# STM32F412xG register map
File version: 1.0
Registers are 32-bit, read-write, reset 0x0 unless marked. A register's access mark holds for its fields unless they carry their own. Offsets are from the block's base; [hi:lo] are bit positions; {n}, {i} and the like mark numbered series; 'fields as' and 'values as' point back to an identical list.

## FSMC — Flexible static memory controller
Base 0x60000000
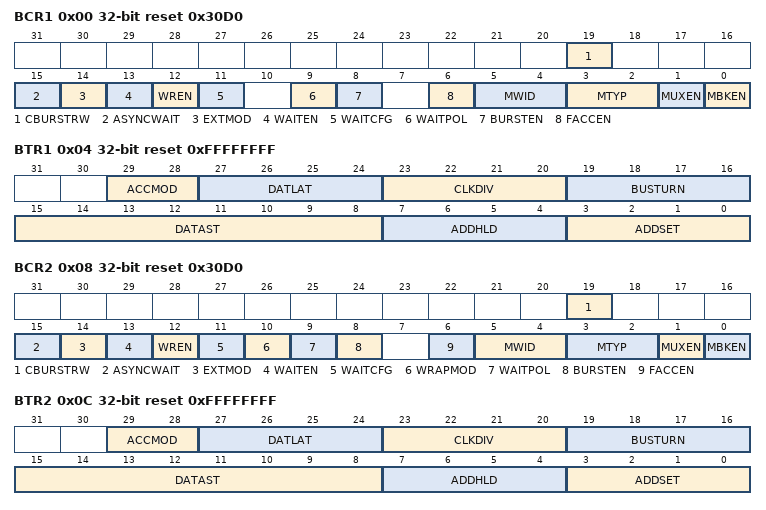
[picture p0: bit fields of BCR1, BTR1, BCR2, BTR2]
0x00 BCR1 reset 0x30D0 — SRAM/NOR-Flash chip-select control register 1
  [19] CBURSTRW, [15] ASYNCWAIT, [14] EXTMOD, [13] WAITEN, [12] WREN, [11] WAITCFG, [9] WAITPOL, [8] BURSTEN, [6] FACCEN, [5:4] MWID, [3:2] MTYP, [1] MUXEN, [0] MBKEN
0x04 BTR1 reset 0xFFFFFFFF — SRAM/NOR-Flash chip-select timing register 1
  [29:28] ACCMOD, [27:24] DATLAT, [23:20] CLKDIV, [19:16] BUSTURN, [15:8] DATAST, [7:4] ADDHLD, [3:0] ADDSET
0x08 BCR2 reset 0x30D0 — SRAM/NOR-Flash chip-select control register 2
  [19] CBURSTRW, [15] ASYNCWAIT, [14] EXTMOD, [13] WAITEN, [12] WREN, [11] WAITCFG, [10] WRAPMOD, [9] WAITPOL, [8] BURSTEN, [6] FACCEN, [5:4] MWID, [3:2] MTYP, [1] MUXEN, [0] MBKEN
0x0C BTR2 reset 0xFFFFFFFF — SRAM/NOR-Flash chip-select timing register 2
  fields as BTR1
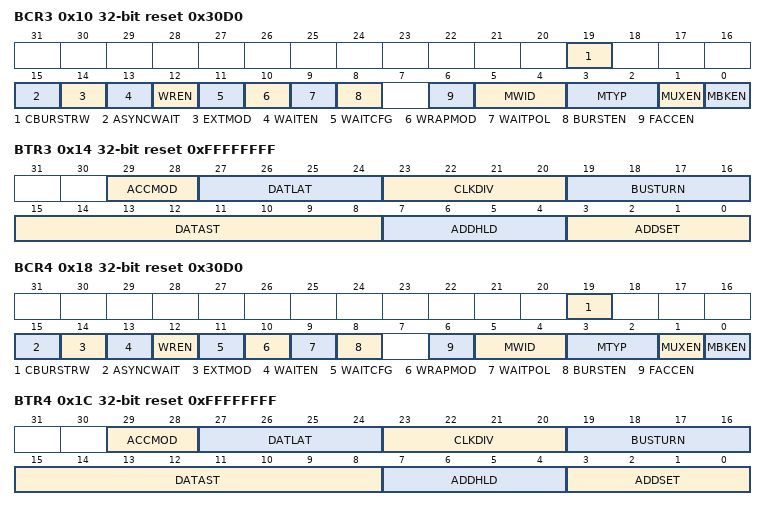
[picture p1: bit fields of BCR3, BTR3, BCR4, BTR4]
0x10 BCR3 reset 0x30D0 — SRAM/NOR-Flash chip-select control register 3
  fields as BCR2
0x14 BTR3 reset 0xFFFFFFFF — SRAM/NOR-Flash chip-select timing register 3
  fields as BTR1
0x18 BCR4 reset 0x30D0 — SRAM/NOR-Flash chip-select control register 4
  fields as BCR2
0x1C BTR4 reset 0xFFFFFFFF — SRAM/NOR-Flash chip-select timing register 4
  fields as BTR1
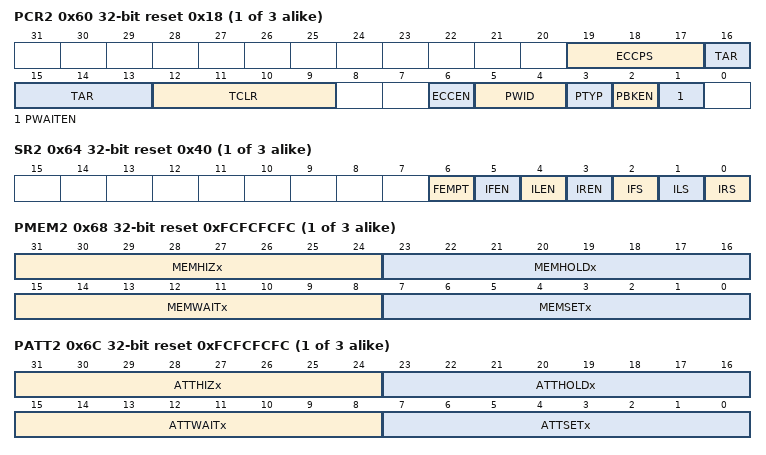
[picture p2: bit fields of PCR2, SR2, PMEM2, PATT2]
{0x20+0x20*i} PCR{i} reset 0x18 (i=2..4) — PC Card/NAND Flash control register {i}
  [19:17] ECCPS, [16:13] TAR, [12:9] TCLR, [6] ECCEN, [5:4] PWID, [3] PTYP, [2] PBKEN, [1] PWAITEN
{0x24+0x20*i} SR{i} access per field reset 0x40 (i=2..4) — FIFO status and interrupt register {i}
  [6] FEMPT ro, [5] IFEN rw, [4] ILEN rw, [3] IREN rw, [2] IFS rw, [1] ILS rw, [0] IRS rw
{0x28+0x20*i} PMEM{i} reset 0xFCFCFCFC (i=2..4) — Common memory space timing register {i}
  [31:24] MEMHIZx, [23:16] MEMHOLDx, [15:8] MEMWAITx, [7:0] MEMSETx
{0x2C+0x20*i} PATT{i} reset 0xFCFCFCFC (i=2..4) — Attribute memory space timing register {i}
  [31:24] ATTHIZx, [23:16] ATTHOLDx, [15:8] ATTWAITx, [7:0] ATTSETx
0x74 ECCR2 ro — ECC result register 2
  [31:0] ECCx
0x94 ECCR3 ro — ECC result register 3
  [31:0] ECCx
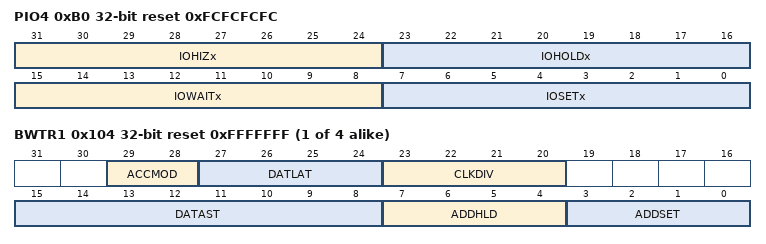
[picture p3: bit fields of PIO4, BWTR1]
0xB0 PIO4 reset 0xFCFCFCFC — I/O space timing register 4
  [31:24] IOHIZx, [23:16] IOHOLDx, [15:8] IOWAITx, [7:0] IOSETx
{0xFC+8i} BWTR{i} reset 0xFFFFFFF (i=1..4) — SRAM/NOR-Flash write timing registers {i}
  [29:28] ACCMOD, [27:24] DATLAT, [23:20] CLKDIV, [15:8] DATAST, [7:4] ADDHLD, [3:0] ADDSET

## OTG_FS_HOST — USB on the go full speed
Base 0x50000400
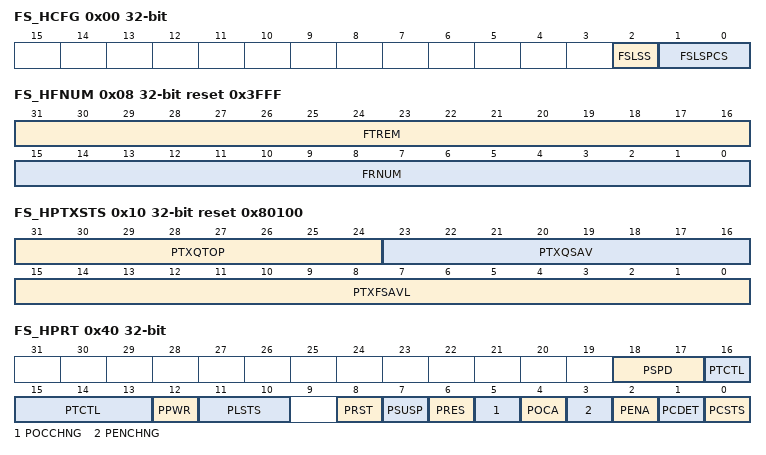
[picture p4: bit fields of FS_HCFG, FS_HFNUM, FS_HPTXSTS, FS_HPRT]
0x00 FS_HCFG access per field — OTG_FS host configuration register (OTG_FS_HCFG)
  [2] FSLSS ro — FS- and LS-only support
  [1:0] FSLSPCS rw — FS/LS PHY clock select
0x04 HFIR reset 0xEA60 — OTG_FS Host frame interval register
  [15:0] FRIVL — Frame interval
0x08 FS_HFNUM ro reset 0x3FFF — OTG_FS host frame number/frame time remaining register (OTG_FS_HFNUM)
  [31:16] FTREM — Frame time remaining
  [15:0] FRNUM — Frame number
0x10 FS_HPTXSTS access per field reset 0x80100 — OTG_FS_Host periodic transmit FIFO/queue status register (OTG_FS_HPTXSTS)
  [31:24] PTXQTOP ro — Top of the periodic transmit request queue
  [23:16] PTXQSAV ro — Periodic transmit request queue space available
  [15:0] PTXFSAVL rw — Periodic transmit data FIFO space available
0x14 HAINT ro — OTG_FS Host all channels interrupt register
  [15:0] HAINT — Channel interrupts
0x18 HAINTMSK — OTG_FS host all channels interrupt mask register
  [15:0] HAINTM — Channel interrupt mask
0x40 FS_HPRT access per field — OTG_FS host port control and status register (OTG_FS_HPRT)
  [18:17] PSPD ro — Port speed
  [16:13] PTCTL rw — Port test control
  [12] PPWR rw — Port power
  [11:10] PLSTS ro — Port line status
  [8] PRST rw — Port reset
  [7] PSUSP rw — Port suspend
  [6] PRES rw — Port resume
  [5] POCCHNG rw — Port overcurrent change
  [4] POCA ro — Port overcurrent active
  [3] PENCHNG rw — Port enable/disable change
  [2] PENA rw — Port enable
  [1] PCDET rw — Port connect detected
  [0] PCSTS ro — Port connect status
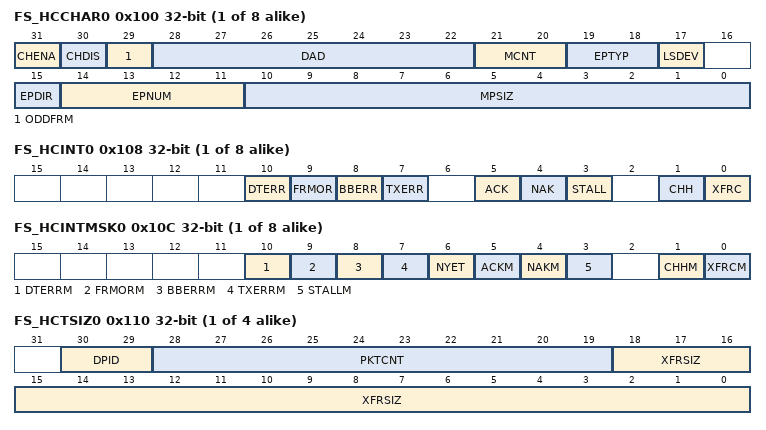
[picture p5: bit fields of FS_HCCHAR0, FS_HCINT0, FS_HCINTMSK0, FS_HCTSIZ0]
{0x100+0x20*i} FS_HCCHAR{i} (i=0..7) — OTG_FS host channel-{i} characteristics register (OTG_FS_HCCHAR{i})
  [31] CHENA — Channel enable
  [30] CHDIS — Channel disable
  [29] ODDFRM — Odd frame
  [28:22] DAD — Device address
  [21:20] MCNT — Multicount
  [19:18] EPTYP — Endpoint type
  [17] LSDEV — Low-speed device
  [15] EPDIR — Endpoint direction
  [14:11] EPNUM — Endpoint number
  [10:0] MPSIZ — Maximum packet size
{0x108+0x20*i} FS_HCINT{i} (i=0..7) — OTG_FS host channel-{i} interrupt register (OTG_FS_HCINT{i})
  [10] DTERR — Data toggle error
  [9] FRMOR — Frame overrun
  [8] BBERR — Babble error
  [7] TXERR — Transaction error
  [5] ACK — ACK response received/transmitted interrupt
  [4] NAK — NAK response received interrupt
  [3] STALL — STALL response received interrupt
  [1] CHH — Channel halted
  [0] XFRC — Transfer completed
{0x10C+0x20*i} FS_HCINTMSK{i} (i=0..7) — OTG_FS host channel-{i} mask register (OTG_FS_HCINTMSK{i})
  [10] DTERRM — Data toggle error mask
  [9] FRMORM — Frame overrun mask
  [8] BBERRM — Babble error mask
  [7] TXERRM — Transaction error mask
  [6] NYET — response received interrupt mask
  [5] ACKM — ACK response received/transmitted interrupt mask
  [4] NAKM — NAK response received interrupt mask
  [3] STALLM — STALL response received interrupt mask
  [1] CHHM — Channel halted mask
  [0] XFRCM — Transfer completed mask
{0x110+0x20*i} FS_HCTSIZ{i} (i=0..3) — OTG_FS host channel-{i} transfer size register
  [30:29] DPID — Data PID
  [28:19] PKTCNT — Packet count
  [18:0] XFRSIZ — Transfer size
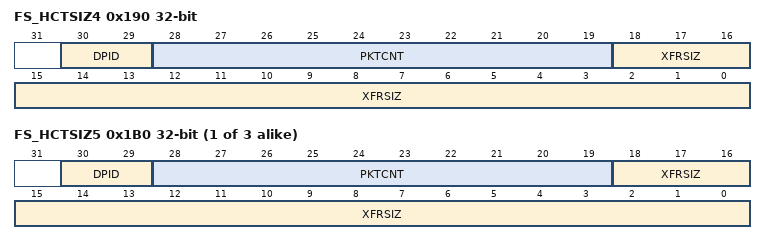
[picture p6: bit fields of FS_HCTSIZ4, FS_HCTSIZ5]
0x190 FS_HCTSIZ4 — OTG_FS host channel-x transfer size register
  fields as FS_HCTSIZ0
{0x110+0x20*i} FS_HCTSIZ{i} (i=5..7) — OTG_FS host channel-{i} transfer size register
  fields as FS_HCTSIZ0

## OTG_FS_PWRCLK — USB on the go full speed
Base 0x50000E00
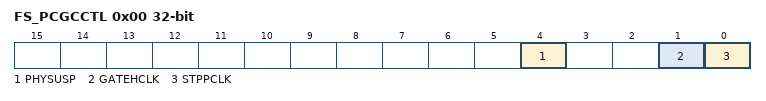
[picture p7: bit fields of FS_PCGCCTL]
0x00 FS_PCGCCTL — OTG_FS power and clock gating control register (OTG_FS_PCGCCTL)
  [4] PHYSUSP — PHY Suspended
  [1] GATEHCLK
  [0] STPPCLK — Stop PHY clock

## QUADSPI — QuadSPI interface
Base 0xA0001000
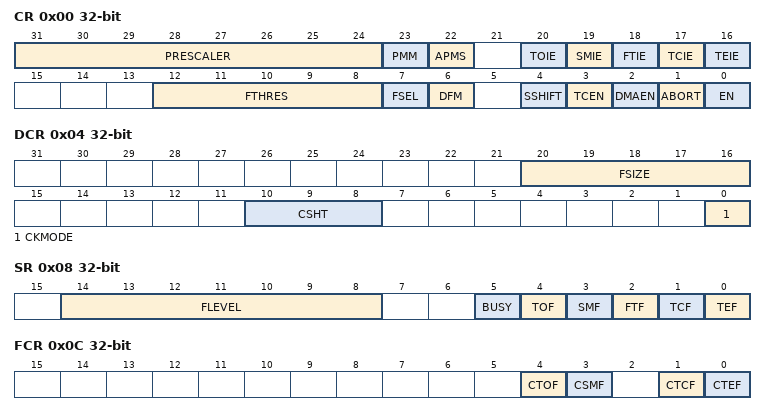
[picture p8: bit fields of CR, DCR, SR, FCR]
0x00 CR — control register
  [31:24] PRESCALER — Clock prescaler
  [23] PMM — Polling match mode
  [22] APMS — Automatic poll mode stop
  [20] TOIE — TimeOut interrupt enable
  [19] SMIE — Status match interrupt enable
  [18] FTIE — FIFO threshold interrupt enable
  [17] TCIE — Transfer complete interrupt enable
  [16] TEIE — Transfer error interrupt enable
  [12:8] FTHRES — IFO threshold level
  [7] FSEL — FLASH memory selection
  [6] DFM — Dual-flash mode
  [4] SSHIFT — Sample shift
  [3] TCEN — Timeout counter enable
  [2] DMAEN — DMA enable
  [1] ABORT — Abort request
  [0] EN — Enable
0x04 DCR — device configuration register
  [20:16] FSIZE — FLASH memory size
  [10:8] CSHT — Chip select high time
  [0] CKMODE — Mode 0 / mode 3
0x08 SR ro — status register
  [14:8] FLEVEL — FIFO level
  [5] BUSY
  [4] TOF — Timeout flag
  [3] SMF — Status match flag
  [2] FTF — FIFO threshold flag
  [1] TCF — Transfer complete flag
  [0] TEF — Transfer error flag
0x0C FCR — flag clear register
  [4] CTOF — Clear timeout flag
  [3] CSMF — Clear status match flag
  [1] CTCF — Clear transfer complete flag
  [0] CTEF — Clear transfer error flag
0x10 DLR — data length register
  [31:0] DL — Data length
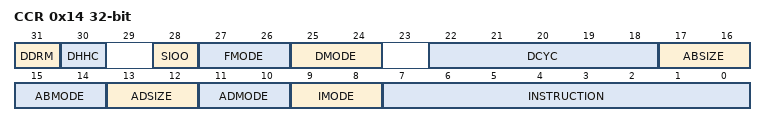
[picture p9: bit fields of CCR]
0x14 CCR — communication configuration register
  [31] DDRM — Double data rate mode
  [30] DHHC — DDR hold half cycle
  [28] SIOO — Send instruction only once mode
  [27:26] FMODE — Functional mode
  [25:24] DMODE — Data mode
  [22:18] DCYC — Number of dummy cycles
  [17:16] ABSIZE — Alternate bytes size
  [15:14] ABMODE — Alternate bytes mode
  [13:12] ADSIZE — Address size
  [11:10] ADMODE — Address mode
  [9:8] IMODE — Instruction mode
  [7:0] INSTRUCTION
0x18 AR — address register
  [31:0] ADDRESS
0x1C ABR
  [31:0] ALTERNATE
0x20 DR — data register
  [31:0] DATA
0x24 PSMKR — polling status mask register
  [31:0] MASK — Status mask
0x28 PSMAR — polling status match register
  [31:0] MATCH — Status match
0x2C PIR — polling interval register
  [15:0] INTERVAL — Polling interval
0x30 LPTR — low-power timeout register
  [15:0] TIMEOUT — Timeout period
